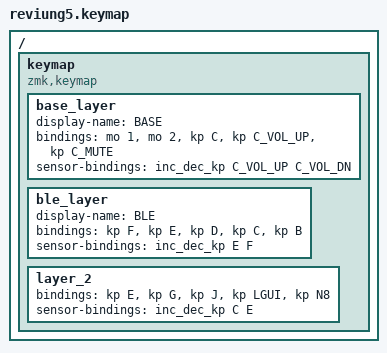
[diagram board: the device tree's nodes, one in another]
/*
 * Copyright (c) 2022 The ZMK Contributors
 *
 * SPDX-License-Identifier: MIT
 */

#include <behaviors.dtsi>
#include <dt-bindings/zmk/keys.h>

#define BASE 0
#define BLE 1

/ {
    keymap {
        compatible = "zmk,keymap";

        base_layer {
            display-name = "BASE";
            bindings = <
&mo 1  &mo 2  &kp C  &kp C_VOL_UP  &kp C_MUTE
            >;

            sensor-bindings = <&inc_dec_kp C_VOL_UP C_VOL_DN>;
        };

        ble_layer {
            display-name = "BLE";
            bindings = <
&kp F  &kp E  &kp D  &kp C  &kp B
            >;

            sensor-bindings = <&inc_dec_kp E F>;
        };

        layer_2 {
            bindings = <
&kp E  &kp G  &kp J  &kp LGUI  &kp N8
            >;

            sensor-bindings = <&inc_dec_kp C E>;
        };
    };
};
